# ATxmega16E5 device description
Architecture: AVR8_XMEGA; Family: AVR XMEGA
Registers are 8-bit, access not given, no defined reset value unless marked. A register's access mark holds for its fields unless they carry their own. Offsets are from the block's base; [hi:lo] are bit positions; lines under a group give offsets from that group; {n}, {i} and the like mark numbered series; 'fields as' and 'values as' point back to an identical list.

## EDMA — Enhanced DMA Controller
Instances: EDMA 0x0100
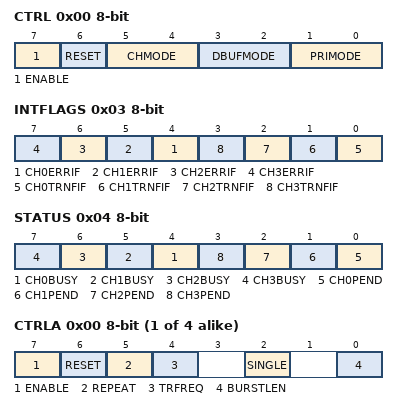
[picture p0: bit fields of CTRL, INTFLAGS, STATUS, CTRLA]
0x00 CTRL — Control
  [7] ENABLE
  [6] RESET — Software Reset
  [5:4] CHMODE — Channel Mode
    0=PER0123 (Channels 0, 1, 2 and 3 in peripheal conf.); 1=STD0 (Channel 0 in standard conf.; channels 2 and 3 in peripheral conf.); 2=STD2 (Channel 2 in standard conf.; channels 0 and 1 in peripheral conf.); 3=STD02 (Channels 0 and 2 in standard conf.)
  [3:2] DBUFMODE — Double Buffer Mode
    0=DISABLE (No double buffer enabled); 1=BUF01 (Double buffer enabled on peripheral channels 0/1 (if exist)); 2=BUF23 (Double buffer enabled on peripheral channels 2/3 (if exist)); 3=BUF0123 (Double buffer enabled on peripheral channels 0/1 and 2/3 or standard channels 0/2)
  [1:0] PRIMODE — Priority Mode
    0=RR0123 (Round robin on all channels); 1=RR123 (Ch0 > round robin (Ch 1 ch2 Ch3)); 2=RR23 (Ch0 > Ch 1 > round robin (Ch2 Ch3)); 3=CH0123 (Ch0 > Ch1 > Ch2 > Ch3)
0x03 INTFLAGS — Transfer Interrupt Status
  [n+4] CH{n}ERRIF (n=0..3) — Channel {n} Transaction Error Interrupt Flag
  [n] CH{n}TRNFIF (n=0..3) — Channel {n} Transaction Complete Interrupt Flag
0x04 STATUS
  [n+4] CH{n}BUSY (n=0..3) — Channel {n} Busy Flag
  [n] CH{n}PEND (n=0..3) — Channel {n} Pending Flag
0x06 TEMP — Temporary Register For 16-bit Access
{0x10+0x10*i} CH{i} group (i=0..3) — EDMA Channel {i}
  0x00 CTRLA — Channel Control A
    [7] ENABLE — Channel Enable
    [6] RESET — Channel Software Reset
    [5] REPEAT — Channel Repeat Mode
    [4] TRFREQ — Channel Transfer Request
    [2] SINGLE — Channel Single Shot Data Transfer
    [0] BURSTLEN — Channel 2-bytes Burst Length
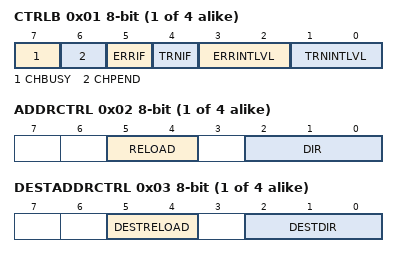
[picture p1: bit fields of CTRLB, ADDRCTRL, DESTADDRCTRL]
  0x01 CTRLB — Channel Control
    [7] CHBUSY — Channel Block Transfer Busy
    [6] CHPEND — Channel Block Transfer Pending
    [5] ERRIF — Channel Transaction Error Interrupt Flag
    [4] TRNIF — Channel Transaction Complete Interrupt Flag
    [3:2] ERRINTLVL — Channel Transaction Error Interrupt Level
      0=OFF (Interrupt disabled); 1=LO (Low level); 2=MED (Medium level); 3=HI (High level)
    [1:0] TRNINTLVL — Channel Transaction Complete Interrupt Level
      values as ERRINTLVL
  0x02 ADDRCTRL — Memory Address Control for Peripheral Ch., or Source Address Control for Standard Ch.
    [5:4] RELOAD — Memory Address Reload for Peripheral Ch., or Source Address Reload for Standard Ch.
      0=NONE (No reload); 1=BLOCK (Reload at end of each block transfer); 2=BURST (Reload at end of each burst transfer); 3=TRANSACTION (Reload at end of each transaction)
    [2:0] DIR — Memory Address Mode for Peripheral Ch., or Source Address Mode for Standard Ch.
      0=FIXED; 1=INC (Increment); 4=MP1 (If Peripheral Ch. (Per ==> Mem), 1-byte 'mask-match' (data: ADDRL, mask: ADDRH), else reserved conf.); 5=MP2 (If Peripheral Ch. (Per ==> Mem), 1-byte 'OR-match' (data-1: ADDRL OR data-2: ADDRH), else reserved conf.); 6=MP3 (If Peripheral Ch. (Per ==> Mem), 2-byte 'match' (data-1: ADDRL followed by data-2: ADDRH), else reserved conf.)
  0x03 DESTADDRCTRL — Destination Address Control for Standard Channels Only.
    [5:4] DESTRELOAD — Destination Address Reload for Standard Channels Only.
      values as CH0.ADDRCTRL.RELOAD
    [2:0] DESTDIR — Destination Address Mode for Standard Channels Only.
      0=FIXED; 1=INC (Increment); 4=MP1 (1-byte 'mask-match' (data: ADDRL, mask: ADDRH)); 5=MP2 (1-byte 'OR-match' (data-1: ADDRL OR data-2: ADDRH)); 6=MP3 (2-byte 'match' (data1: ADDRL followed by data2: ADDRH))
  0x04 TRIGSRC — Channel Trigger Source
    [7:0] TRIGSRC
      0=OFF (Software triggers only); 1=EVSYS_CH0 (Event CH0 as trigger (Standard Channels Only)); 2=EVSYS_CH1 (Event CH1 as trigger (Standard Channels Only)); 3=EVSYS_CH2 (Event CH2 as trigger (Standard Channels Only)); 16=ADCA_CH0 (ADCA CH0 as trigger); 21=DACA_CH0 (DACA CH0 as trigger); 22=DACA_CH1 (DACA CH1 as trigger); 64=TCC4_OVF (TCC4 overflow/underflow as trigger (Standard Channels Only)); 65=TCC4_ERR (TCC4 error as trigger (Standard Channels Only)); 66=TCC4_CCA (TCC4 compare or capture channel A as trigger (Standard Channels Only)); 67=TCC4_CCB (TCC4 compare or capture channel B as trigger (Standard Channels Only)); 68=TCC4_CCC (TCC4 compare or capture channel C as trigger (Standard Channels Only)); 69=TCC4_CCD (TCC4 compare or capture channel D as trigger (Standard Channels Only)); 70=TCC5_OVF (TCC5 overflow/underflow as trigger (Standard Channels Only)); 71=TCC5_ERR (TCC5 error as trigger (Standard Channels Only)); 72=TCC5_CCA (TCC5 compare or capture channel A as trigger (Standard Channels Only)); 73=TCC5_CCB (TCC5 compare or capture channel B as trigger (Standard Channels Only)); 74=SPIC_RXC (SPI C transfer complete (SPI Standard Mode) or SPI C receive complete as trigger (SPI Buffer Modes)); 75=SPIC_DRE (SPI C transfer complete (SPI Standard Mode) or SPI C data register empty as trigger (SPI Buffer modes)); 76=USARTC0_RXC (USART C0 receive complete as trigger); 77=USARTC0_DRE (USART C0 data register empty as trigger); 102=TCD5_OVF (TCD5 overflow/underflow as trigger (Standard Channels Only)); 103=TCD5_ERR (TCD5 error as trigger (Standard Channels Only)); 104=TCD5_CCA (TCD5 compare or capture channel A as trigger (Standard Channels Only)); 105=TCD5_CCB (TCD5 compare or capture channel B as trigger (Standard Channels Only)); 108=USARTD0_RXC (USART D0 receive complete as trigger); 109=USARTD0_DRE (USART D0 data register empty as trigger)
  0x06 TRFCNT 16-bit — Channel Block Transfer Count for Peripheral Ch., or Channel Block Transfer Count Low for Standard Ch.
  0x08 ADDR 16-bit — Channel Memory Address for Peripheral Ch., or Channel Source Address Low for Standard Ch.
  0x0C DESTADDR 16-bit — Channel Destination Address for Standard Channels Only.
